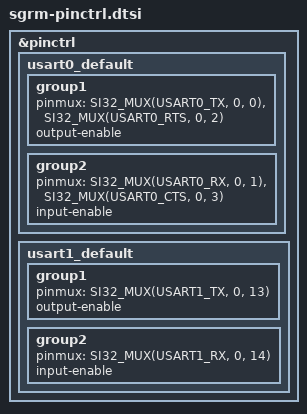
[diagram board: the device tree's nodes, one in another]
/*
 * Copyright (c) 2024 GARDENA GmbH
 *
 * SPDX-License-Identifier: Apache-2.0
 */

#include <zephyr/dt-bindings/pinctrl/si32-pinctrl.h>

&pinctrl {
	usart0_default: usart0_default {
		group1 {
			pinmux = <SI32_MUX(USART0_TX, 0, 0)>,
				 <SI32_MUX(USART0_RTS, 0, 2)>;
			output-enable;
		};

		group2 {
			pinmux = <SI32_MUX(USART0_RX, 0, 1)>,
				 <SI32_MUX(USART0_CTS, 0, 3)>;
			input-enable;
		};
	};

	usart1_default: usart1_default {
		group1 {
			pinmux = <SI32_MUX(USART1_TX, 0, 13)>;
			output-enable;
		};

		group2 {
			pinmux = <SI32_MUX(USART1_RX, 0, 14)>;
			input-enable;
		};
	};
};
